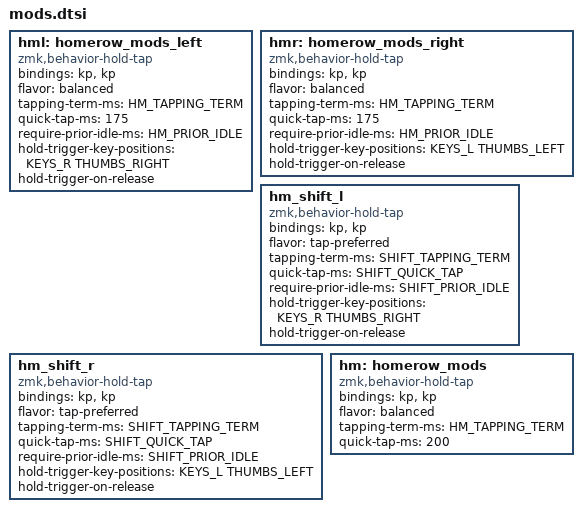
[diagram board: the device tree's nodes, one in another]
#define KEYS_L 0 1 2 3 4 5 6 14 15 16 17 18 19 20 28 29 30 31 32 33 34 46 47 48 49 50 51 60 61 62 63 64
#define THUMBS_LEFT 35 36 52 65 66 67
#define KEYS_R 7 8 9 10 11 12 13 21 22 23 24 25 26 27 39 40 41 42 43 44 45 54 55 56 57 58 59 71 72 73 74 75
#define THUMBS_RIGHT 37 38 53 68 69 70

#define HM_TAPPING_TERM 300
#define HM_TAPPING_TERM_FAST 200
#define HM_PRIOR_IDLE 150
#define HM_PRIOR_IDLE_FAST 100

// Based on Sunaku's settings
#define SHIFT_TAPPING_TERM 170     // Faster than regular homerow mods
#define SHIFT_QUICK_TAP 150        // Allow quick repeat taps
#define SHIFT_PRIOR_IDLE 120       // Shorter idle requirement for shifts

// Positional Homerow mods
// Homerow mods that prevent accidental activations when rolling keys,
// such as when typing `st` or `ne` on colemak-dh layouts or `as` on
// qwerty.
//
// Works by only allowing a mod to activate within tapping-term if
// it's on the opposite side of the keyboard or on the same side thumb
// keys.

// Further optimization using urob's timerless homerow mods method:
// https://github.com/urob/zmk-config#timeless-homerow-mods
hml: homerow_mods_left {
    compatible = "zmk,behavior-hold-tap";
    #binding-cells = <2>;
    bindings = <&kp>,  <&kp>;

    flavor = "balanced";
    tapping-term-ms = <HM_TAPPING_TERM>;
    quick-tap-ms = <175>;                // repeat on tap-into-hold
    require-prior-idle-ms = <HM_PRIOR_IDLE>;

    hold-trigger-key-positions = <KEYS_R THUMBS_RIGHT>;
    hold-trigger-on-release;
};

hmr: homerow_mods_right {
    compatible = "zmk,behavior-hold-tap";
    #binding-cells = <2>;
    bindings = <&kp>, <&kp>;

    flavor = "balanced";
    tapping-term-ms = <HM_TAPPING_TERM>;
    quick-tap-ms = <175>;
    require-prior-idle-ms = <HM_PRIOR_IDLE>;

    hold-trigger-key-positions = <KEYS_L THUMBS_LEFT>;
    hold-trigger-on-release;
};

hm_shift_l: hm_shift_l {
    compatible = "zmk,behavior-hold-tap";
    #binding-cells = <2>;
    bindings = <&kp>, <&kp>;
    
    flavor = "tap-preferred";      // Sunaku uses tap-preferred for shifts
    tapping-term-ms = <SHIFT_TAPPING_TERM>;
    quick-tap-ms = <SHIFT_QUICK_TAP>;
    require-prior-idle-ms = <SHIFT_PRIOR_IDLE>;
    
    hold-trigger-key-positions = <KEYS_R THUMBS_RIGHT>;
    hold-trigger-on-release;       // Wait for other home row mods
};

hm_shift_r: hm_shift_r {
    compatible = "zmk,behavior-hold-tap";
    #binding-cells = <2>;
    bindings = <&kp>, <&kp>;
    
    flavor = "tap-preferred";      // Tap-preferred for more responsive typing
    tapping-term-ms = <SHIFT_TAPPING_TERM>;
    quick-tap-ms = <SHIFT_QUICK_TAP>;
    require-prior-idle-ms = <SHIFT_PRIOR_IDLE>;
    
    hold-trigger-key-positions = <KEYS_L THUMBS_LEFT>;
    hold-trigger-on-release;       // Wait for other home row mods
};

/*
  * Non-Positional Homerow Mods
  * Used for &mm_grescm_gui behavior on left hand.
  *
  * Usage: &hm LSHFT T
  * Tap: T
  * Tap-Tap-Hold: Repeat T
  * Hold: LSHIFT
  */
hm: homerow_mods {
    compatible = "zmk,behavior-hold-tap";
    #binding-cells = <2>;
    bindings = <&kp>, <&kp>;

    flavor = "balanced";
    tapping-term-ms = <HM_TAPPING_TERM>;
    quick-tap-ms = <200>;
};
